VERSION "V1.7.4"

NS_ :

BS_:

BU_: DC RL RR FL FR

BO_ 1633 CAL_Static_Result_RR: 64 Vector__XXX
 SG_ CAL_start_calib_id_RR : 7|8@0+ (1,0) [0|255] "" Vector__XXX

BO_ 1121 CAL_Static_Result_RL: 64 Vector__XXX
 SG_ CAL_start_calib_id_RL : 7|8@0+ (1,0) [0|255] "" Vector__XXX

BO_ 609 CAL_Static_Result_FR: 64 Vector__XXX
 SG_ CAL_start_calib_id_FR : 7|8@0+ (1,0) [0|255] "" Vector__XXX

BO_ 97 CAL_Static_Result_FL: 64 Vector__XXX
 SG_ CAL_start_calib_id_FL : 7|8@0+ (1,0) [0|255] "" Vector__XXX

BO_ 1632 CAL_Cfg_RR: 64 Vector__XXX
 SG_ CAL_calib_id_RR : 7|8@0+ (1,0) [0|255] "" Vector__XXX
 SG_ CAL_vehicle_height_RR : 15|32@0- (1,0) [-3.4E+038|3.4E+038] ""  RR
 SG_ CAL_reserve5_RR : 455|64@0+ (1,0) [0|1.84467440737096E+019] ""  RR
 SG_ CAL_reserve4_RR : 391|64@0+ (1,0) [0|1.84467440737096E+019] ""  RR
 SG_ CAL_reserve3_RR : 327|64@0+ (1,0) [0|1.84467440737096E+019] ""  RR
 SG_ CAL_reserve2_RR : 263|64@0+ (1,0) [0|1.84467440737096E+019] ""  RR
 SG_ CAL_reserve1_RR : 239|24@0+ (1,0) [0|16777215] ""  RR
 SG_ CAL_radar_z_offset_RR : 111|32@0- (1,0) [-3.4E+038|3.4E+038] ""  RR
 SG_ CAL_radar_yaw_angle_RR : 143|32@0- (1,0) [-3.4E+038|3.4E+038] ""  RR
 SG_ CAL_radar_y_offset_RR : 79|32@0- (1,0) [-3.4E+038|3.4E+038] ""  RR
 SG_ CAL_radar_x_offset_RR : 47|32@0- (1,0) [-3.4E+038|3.4E+038] ""  RR
 SG_ CAL_radar_roll_angle_RR : 207|32@0- (1,0) [-3.4E+038|3.4E+038] ""  RR
 SG_ CAL_radar_pitch_angle_RR : 175|32@0- (1,0) [-3.4E+038|3.4E+038] ""  RR

BO_ 1120 CAL_Cfg_RL: 64 Vector__XXX
 SG_ CAL_calib_id_RL : 7|8@0+ (1,0) [0|255] "" Vector__XXX
 SG_ CAL_vehicle_height_RL : 15|32@0- (1,0) [-3.4E+038|3.4E+038] ""  RL
 SG_ CAL_reserve5_RL : 455|64@0+ (1,0) [0|1.84467440737096E+019] ""  RL
 SG_ CAL_reserve4_RL : 391|64@0+ (1,0) [0|1.84467440737096E+019] ""  RL
 SG_ CAL_reserve3_RL : 327|64@0+ (1,0) [0|1.84467440737096E+019] ""  RL
 SG_ CAL_reserve2_RL : 263|64@0+ (1,0) [0|1.84467440737096E+019] ""  RL
 SG_ CAL_reserve1_RL : 239|24@0+ (1,0) [0|16777215] ""  RL
 SG_ CAL_radar_z_offset_RL : 111|32@0- (1,0) [-3.4E+038|3.4E+038] ""  RL
 SG_ CAL_radar_yaw_angle_RL : 143|32@0- (1,0) [-3.4E+038|3.4E+038] ""  RL
 SG_ CAL_radar_y_offset_RL : 79|32@0- (1,0) [-3.4E+038|3.4E+038] ""  RL
 SG_ CAL_radar_x_offset_RL : 47|32@0- (1,0) [-3.4E+038|3.4E+038] ""  RL
 SG_ CAL_radar_roll_angle_RL : 207|32@0- (1,0) [-3.4E+038|3.4E+038] ""  RL
 SG_ CAL_radar_pitch_angle_RL : 175|32@0- (1,0) [-3.4E+038|3.4E+038] ""  RL

BO_ 608 CAL_Cfg_FR: 64 Vector__XXX
 SG_ CAL_calib_id_FR : 7|8@0+ (1,0) [0|255] "" Vector__XXX
 SG_ CAL_vehicle_height_FR : 15|32@0- (1,0) [-3.4E+038|3.4E+038] ""  FR
 SG_ CAL_reserve5_FR : 455|64@0+ (1,0) [0|1.84467440737096E+019] ""  FR
 SG_ CAL_reserve4_FR : 391|64@0+ (1,0) [0|1.84467440737096E+019] ""  FR
 SG_ CAL_reserve3_FR : 327|64@0+ (1,0) [0|1.84467440737096E+019] ""  FR
 SG_ CAL_reserve2_FR : 263|64@0+ (1,0) [0|1.84467440737096E+019] ""  FR
 SG_ CAL_reserve1_FR : 239|24@0+ (1,0) [0|16777215] ""  FR
 SG_ CAL_radar_z_offset_FR : 111|32@0- (1,0) [-3.4E+038|3.4E+038] ""  FR
 SG_ CAL_radar_yaw_angle_FR : 143|32@0- (1,0) [-3.4E+038|3.4E+038] ""  FR
 SG_ CAL_radar_y_offset_FR : 79|32@0- (1,0) [-3.4E+038|3.4E+038] ""  FR
 SG_ CAL_radar_x_offset_FR : 47|32@0- (1,0) [-3.4E+038|3.4E+038] ""  FR
 SG_ CAL_radar_roll_angle_FR : 207|32@0- (1,0) [-3.4E+038|3.4E+038] ""  FR
 SG_ CAL_radar_pitch_angle_FR : 175|32@0- (1,0) [-3.4E+038|3.4E+038] ""  FR

BO_ 96 CAL_Cfg_FL: 64 Vector__XXX
 SG_ CAL_calib_id_FL : 7|8@0+ (1,0) [0|255] "" Vector__XXX
 SG_ CAL_vehicle_height_FL : 15|32@0- (1,0) [-3.4E+038|3.4E+038] ""  FL
 SG_ CAL_reserve5_FL : 455|64@0+ (1,0) [0|1.84467440737096E+019] ""  FL
 SG_ CAL_reserve4_FL : 391|64@0+ (1,0) [0|1.84467440737096E+019] ""  FL
 SG_ CAL_reserve3_FL : 327|64@0+ (1,0) [0|1.84467440737096E+019] ""  FL
 SG_ CAL_reserve2_FL : 263|64@0+ (1,0) [0|1.84467440737096E+019] ""  FL
 SG_ CAL_reserve1_FL : 239|24@0+ (1,0) [0|16777215] ""  FL
 SG_ CAL_radar_z_offset_FL : 111|32@0- (1,0) [-3.4E+038|3.4E+038] ""  FL
 SG_ CAL_radar_yaw_angle_FL : 143|32@0- (1,0) [-3.4E+038|3.4E+038] ""  FL
 SG_ CAL_radar_y_offset_FL : 79|32@0- (1,0) [-3.4E+038|3.4E+038] ""  FL
 SG_ CAL_radar_x_offset_FL : 47|32@0- (1,0) [-3.4E+038|3.4E+038] ""  FL
 SG_ CAL_radar_roll_angle_FL : 207|32@0- (1,0) [-3.4E+038|3.4E+038] ""  FL
 SG_ CAL_radar_pitch_angle_FL : 175|32@0- (1,0) [-3.4E+038|3.4E+038] ""  FL

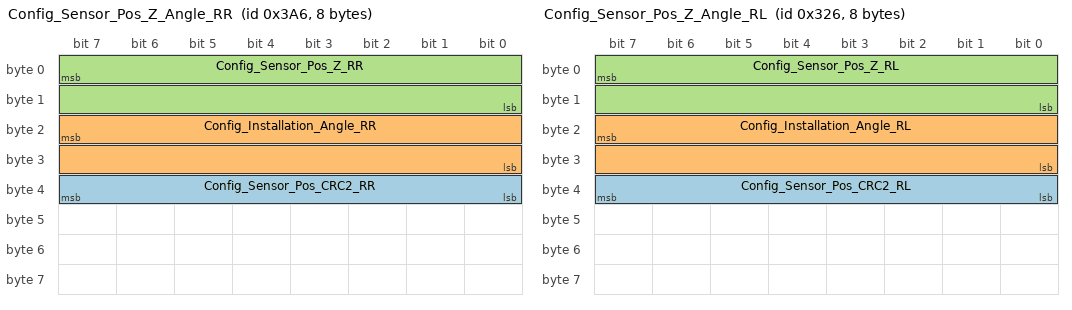
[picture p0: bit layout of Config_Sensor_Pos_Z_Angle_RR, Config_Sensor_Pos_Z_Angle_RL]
BO_ 934 Config_Sensor_Pos_Z_Angle_RR: 8 DC
 SG_ Config_Sensor_Pos_CRC2_RR : 39|8@0+ (1,0) [0|255] "N/A"  RR
 SG_ Config_Installation_Angle_RR : 23|16@0+ (1,-1800) [-1800|1800] "mm"  RR
 SG_ Config_Sensor_Pos_Z_RR : 7|16@0+ (1,0) [250|2000] "mm"  RR

BO_ 806 Config_Sensor_Pos_Z_Angle_RL: 8 DC
 SG_ Config_Sensor_Pos_CRC2_RL : 39|8@0+ (1,0) [0|255] "N/A"  RL
 SG_ Config_Installation_Angle_RL : 23|16@0+ (1,-1800) [-1800|1800] "mm"  RL
 SG_ Config_Sensor_Pos_Z_RL : 7|16@0+ (1,0) [250|2000] "mm"  RL

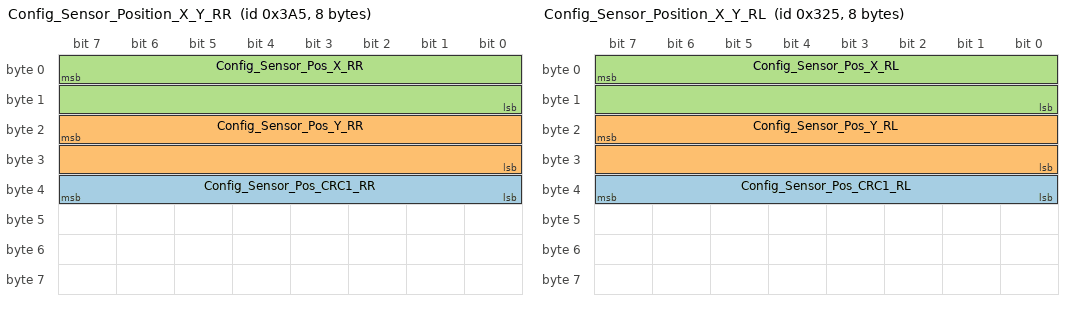
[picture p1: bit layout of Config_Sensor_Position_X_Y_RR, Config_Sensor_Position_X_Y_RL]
BO_ 933 Config_Sensor_Position_X_Y_RR: 8 DC
 SG_ Config_Sensor_Pos_CRC1_RR : 39|8@0+ (1,0) [0|255] "N/A"  RR
 SG_ Config_Sensor_Pos_Y_RR : 23|16@0+ (1,-20000) [-20000|20000] "mm"  RR
 SG_ Config_Sensor_Pos_X_RR : 7|16@0+ (1,-20000) [-20000|20000] "mm"  RR

BO_ 805 Config_Sensor_Position_X_Y_RL: 8 DC
 SG_ Config_Sensor_Pos_CRC1_RL : 39|8@0+ (1,0) [0|255] "N/A"  RL
 SG_ Config_Sensor_Pos_Y_RL : 23|16@0+ (1,-20000) [-20000|20000] "mm"  RL
 SG_ Config_Sensor_Pos_X_RL : 7|16@0+ (1,-20000) [-20000|20000] "mm"  RL

BO_ 32 Config_Mode_RR: 8 DC
 SG_ Config_Mode_CRC_RR : 15|8@0+ (1,0) [0|255] "N/A"  RR
 SG_ Config_Mode_Flag_RR : 7|8@0+ (1,0) [0|1] "N/A"  RR

BO_ 28 Config_Mode_RL: 8 DC
 SG_ Config_Mode_CRC_RL : 15|8@0+ (1,0) [0|255] "N/A"  RL
 SG_ Config_Mode_Flag_RL : 7|8@0+ (1,0) [0|1] "N/A"  RL

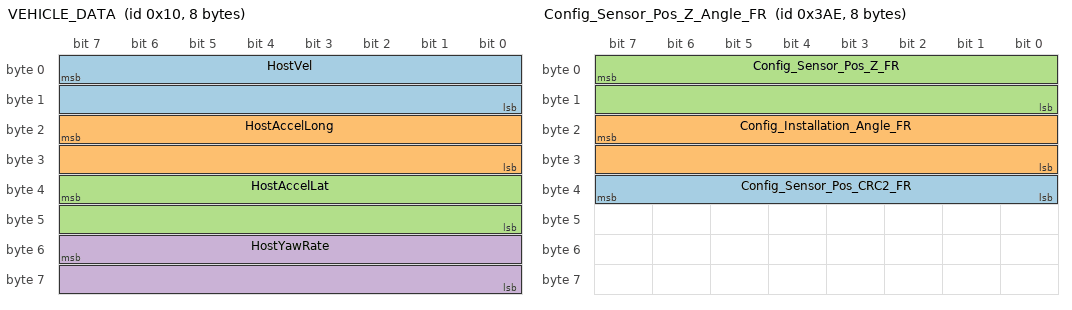
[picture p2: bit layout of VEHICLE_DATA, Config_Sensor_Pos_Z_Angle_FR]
BO_ 16 VEHICLE_DATA: 8 DC
 SG_ HostVel : 7|16@0+ (1,-2000) [-2000|14000] "cm/s"  FR,FL,RR,RL
 SG_ HostAccelLong : 23|16@0+ (1,-2000) [-2000|2000] "cm/s.s"  FR,FL,RR,RL
 SG_ HostAccelLat : 39|16@0+ (1,-2000) [-2000|2000] "cm/s.s"  FR,FL,RR,RL
 SG_ HostYawRate : 55|16@0+ (1,-2048) [-2048|2047] "1/1024 rad/sec"  FR,FL,RR,RL

BO_ 942 Config_Sensor_Pos_Z_Angle_FR: 8 DC
 SG_ Config_Sensor_Pos_CRC2_FR : 39|8@0+ (1,0) [0|255] "N/A"  FR
 SG_ Config_Installation_Angle_FR : 23|16@0+ (1,-1800) [-1800|1800] "mm"  FR
 SG_ Config_Sensor_Pos_Z_FR : 7|16@0+ (1,0) [250|2000] "mm"  FR

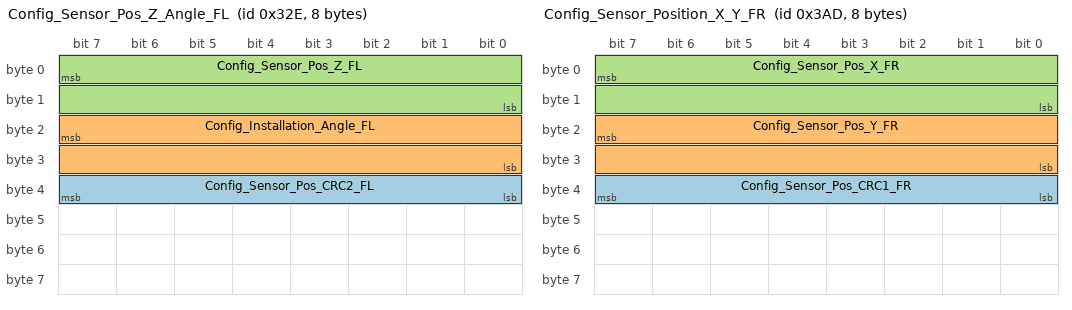
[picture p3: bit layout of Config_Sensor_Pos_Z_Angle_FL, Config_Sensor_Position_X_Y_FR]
BO_ 814 Config_Sensor_Pos_Z_Angle_FL: 8 DC
 SG_ Config_Sensor_Pos_CRC2_FL : 39|8@0+ (1,0) [0|255] "N/A"  FL
 SG_ Config_Installation_Angle_FL : 23|16@0+ (1,-1800) [-1800|1800] "mm"  FL
 SG_ Config_Sensor_Pos_Z_FL : 7|16@0+ (1,0) [250|2000] "mm"  FL

BO_ 941 Config_Sensor_Position_X_Y_FR: 8 DC
 SG_ Config_Sensor_Pos_CRC1_FR : 39|8@0+ (1,0) [0|255] "N/A"  FR
 SG_ Config_Sensor_Pos_Y_FR : 23|16@0+ (1,-20000) [-20000|20000] "mm"  FR
 SG_ Config_Sensor_Pos_X_FR : 7|16@0+ (1,-20000) [-20000|20000] "mm"  FR

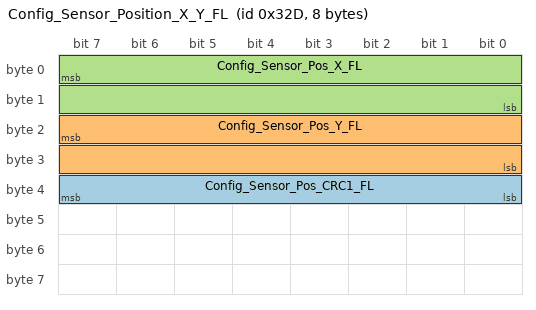
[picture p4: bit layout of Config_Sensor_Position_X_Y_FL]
BO_ 813 Config_Sensor_Position_X_Y_FL: 8 DC
 SG_ Config_Sensor_Pos_CRC1_FL : 39|8@0+ (1,0) [0|255] "N/A"  FL
 SG_ Config_Sensor_Pos_Y_FL : 23|16@0+ (1,-20000) [-20000|20000] "mm"  FL
 SG_ Config_Sensor_Pos_X_FL : 7|16@0+ (1,-20000) [-20000|20000] "mm"  FL

BO_ 24 Config_Mode_FR: 8 DC
 SG_ Config_Mode_CRC_FR : 15|8@0+ (1,0) [0|255] "N/A"  FR
 SG_ Config_Mode_Flag_FR : 7|8@0+ (1,0) [0|1] "N/A"  FR

BO_ 20 Config_Mode_FL: 8 DC
 SG_ Config_Mode_CRC_FL : 15|8@0+ (1,0) [0|255] "N/A"  FL
 SG_ Config_Mode_Flag_FL : 7|8@0+ (1,0) [0|1] "N/A"  FL

BO_ 85 Check_History_Error: 2 DC
 SG_ Check_CRC : 15|8@0+ (1,0) [0|255] ""  RR,RL,FR,FL
 SG_ Check_Request_Error : 7|8@0+ (1,0) [0|255] ""  RR,RL,FR,FL

BO_ 50 Diag_Hist_Error_Clear_FR: 20 DC
 SG_ Error_Clear_CRC_FR : 135|8@0+ (1,0) [0|255] ""  FR
 SG_ O_POPC_Index_Clear_FR : 119|8@0+ (1,0) [0|255] ""  FR
 SG_ O_POPC_Clear_FR : 107|4@0+ (1,0) [0|15] ""  FR
 SG_ O_PRPC_SIDI_Clear_FR : 111|4@0+ (1,0) [0|15] ""  FR
 SG_ O_PRPC_INV_Clear_FR : 99|4@0+ (1,0) [0|15] ""  FR
 SG_ O_Reset_Clear_FR : 103|4@0+ (1,0) [0|15] ""  FR
 SG_ P_INV_Intrinsics_Clear_FR : 75|4@0+ (1,0) [0|15] ""  FR
 SG_ P_INV_Memory_Clear_FR : 67|4@0+ (1,0) [0|15] ""  FR
 SG_ C_CAN_BusOff_Clear_FR : 31|4@0+ (1,0) [0|15] ""  FR
 SG_ C_CAN_Error_Clear_FR : 19|4@0+ (1,0) [0|15] ""  FR
 SG_ H_PMIC_Volt_Clear_FR : 15|4@0+ (1,0) [0|15] ""  FR
 SG_ H_Under_Volt_Clear_FR : 3|4@0+ (1,0) [0|15] ""  FR
 SG_ H_Over_Volt_Clear_FR : 7|4@0+ (1,0) [0|15] ""  FR

BO_ 49 Diag_Hist_Error_Clear_FL: 20 DC
 SG_ Error_Clear_CRC_FL : 135|8@0+ (1,0) [0|255] ""  FL
 SG_ O_POPC_Index_Clear_FL : 119|8@0+ (1,0) [0|255] ""  FL
 SG_ O_POPC_Clear_FL : 107|4@0+ (1,0) [0|15] ""  FL
 SG_ O_PRPC_SIDI_Clear_FL : 111|4@0+ (1,0) [0|15] ""  FL
 SG_ O_PRPC_INV_Clear_FL : 99|4@0+ (1,0) [0|15] ""  FL
 SG_ O_Reset_Clear_FL : 103|4@0+ (1,0) [0|15] ""  FL
 SG_ P_INV_Intrinsics_Clear_FL : 75|4@0+ (1,0) [0|15] ""  FL
 SG_ P_INV_Memory_Clear_FL : 67|4@0+ (1,0) [0|15] ""  FL
 SG_ C_CAN_BusOff_Clear_FL : 31|4@0+ (1,0) [0|15] ""  FL
 SG_ C_CAN_Error_Clear_FL : 19|4@0+ (1,0) [0|15] ""  FL
 SG_ H_PMIC_Volt_Clear_FL : 15|4@0+ (1,0) [0|15] ""  FL
 SG_ H_Under_Volt_Clear_FL : 3|4@0+ (1,0) [0|15] ""  FL
 SG_ H_Over_Volt_Clear_FL : 7|4@0+ (1,0) [0|15] ""  FL

BO_ 52 Diag_Hist_Error_Clear_RR: 20 DC
 SG_ Error_Clear_CRC_RR : 135|8@0+ (1,0) [0|255] ""  RR
 SG_ O_POPC_Index_Clear_RR : 119|8@0+ (1,0) [0|255] ""  RR
 SG_ O_POPC_Clear_RR : 107|4@0+ (1,0) [0|15] ""  RR
 SG_ O_PRPC_SIDI_Clear_RR : 111|4@0+ (1,0) [0|15] ""  RR
 SG_ O_PRPC_INV_Clear_RR : 99|4@0+ (1,0) [0|15] ""  RR
 SG_ O_Reset_Clear_RR : 103|4@0+ (1,0) [0|15] ""  RR
 SG_ P_INV_Intrinsics_Clear_RR : 75|4@0+ (1,0) [0|15] ""  RR
 SG_ P_INV_Memory_Clear_RR : 67|4@0+ (1,0) [0|15] ""  RR
 SG_ C_CAN_BusOff_Clear_RR : 31|4@0+ (1,0) [0|15] ""  RR
 SG_ C_CAN_Error_Clear_RR : 19|4@0+ (1,0) [0|15] ""  RR
 SG_ H_PMIC_Volt_Clear_RR : 15|4@0+ (1,0) [0|15] ""  RR
 SG_ H_Under_Volt_Clear_RR : 3|4@0+ (1,0) [0|15] ""  RR
 SG_ H_Over_Volt_Clear_RR : 7|4@0+ (1,0) [0|15] ""  RR

BO_ 51 Diag_Hist_Error_Clear_RL: 20 DC
 SG_ Error_Clear_CRC_RL : 135|8@0+ (1,0) [0|255] ""  RL
 SG_ O_POPC_Index_Clear_RL : 119|8@0+ (1,0) [0|255] ""  RL
 SG_ O_POPC_Clear_RL : 107|4@0+ (1,0) [0|15] ""  RL
 SG_ O_PRPC_SIDI_Clear_RL : 111|4@0+ (1,0) [0|15] ""  RL
 SG_ O_PRPC_INV_Clear_RL : 99|4@0+ (1,0) [0|15] ""  RL
 SG_ O_Reset_Clear_RL : 103|4@0+ (1,0) [0|15] ""  RL
 SG_ P_INV_Intrinsics_Clear_RL : 75|4@0+ (1,0) [0|15] ""  RL
 SG_ P_INV_Memory_Clear_RL : 67|4@0+ (1,0) [0|15] ""  RL
 SG_ C_CAN_BusOff_Clear_RL : 31|4@0+ (1,0) [0|15] ""  RL
 SG_ C_CAN_Error_Clear_RL : 19|4@0+ (1,0) [0|15] ""  RL
 SG_ H_PMIC_Volt_Clear_RL : 15|4@0+ (1,0) [0|15] ""  RL
 SG_ H_Under_Volt_Clear_RL : 3|4@0+ (1,0) [0|15] ""  RL
 SG_ H_Over_Volt_Clear_RL : 7|4@0+ (1,0) [0|15] ""  RL

CM_ BO_ 934 "Configure the Z Position and Installation Angle of the Radar";
CM_ SG_ 934 Config_Sensor_Pos_CRC2_RR "CRC";
CM_ SG_ 934 Config_Installation_Angle_RR "Ten Times the Actual Value of  Installation Angle in deg";
CM_ SG_ 934 Config_Sensor_Pos_Z_RR "The Actual Value of  Z Position in mm";
CM_ BO_ 806 "Configure the Z Position and Installation Angle of the Radar";
CM_ SG_ 806 Config_Sensor_Pos_CRC2_RL "CRC";
CM_ SG_ 806 Config_Installation_Angle_RL "Ten Times the Actual Value of  Installation Angle in deg";
CM_ SG_ 806 Config_Sensor_Pos_Z_RL "The Actual Value of  Z Position in mm";
CM_ BO_ 933 "Configure the X Position and Y Position of the Radar";
CM_ SG_ 933 Config_Sensor_Pos_CRC1_RR "CRC";
CM_ SG_ 933 Config_Sensor_Pos_Y_RR "The Actual Value of  Y Position in mm";
CM_ SG_ 933 Config_Sensor_Pos_X_RR "The Actual Value of  X Position in mm";
CM_ BO_ 805 "Configure the X Position and Y Position of the Radar";
CM_ SG_ 805 Config_Sensor_Pos_CRC1_RL "CRC";
CM_ SG_ 805 Config_Sensor_Pos_Y_RL "The Actual Value of  Y Position in mm";
CM_ SG_ 805 Config_Sensor_Pos_X_RL "The Actual Value of  X Position in mm";
CM_ BO_ 32 "Configure the Radar to Config Mode or Normal Mode";
CM_ SG_ 32 Config_Mode_CRC_RR "CRC";
CM_ SG_ 32 Config_Mode_Flag_RR "0: Normal Mode
1: Config Mode";
CM_ BO_ 28 "Configure the Radar to Config Mode or Normal Mode";
CM_ SG_ 28 Config_Mode_CRC_RL "CRC";
CM_ SG_ 28 Config_Mode_Flag_RL "0: Normal Mode
1: Config Mode";
CM_ BO_ 16 "Contains the Vehicle Data";
CM_ SG_ 16 HostVel "Host velocity";
CM_ SG_ 16 HostAccelLong "Longitudinal host acceleration in cm/s^2";
CM_ SG_ 16 HostAccelLat "Lateral host acceleration in cm/s^2";
CM_ SG_ 16 HostYawRate "Host yaw rate in 1/1024 rad/s";
CM_ BO_ 942 "Configure the Z Position and Installation Angle of the Radar";
CM_ SG_ 942 Config_Sensor_Pos_CRC2_FR "CRC";
CM_ SG_ 942 Config_Installation_Angle_FR "Ten Times the Actual Value of  Installation Angle in deg";
CM_ SG_ 942 Config_Sensor_Pos_Z_FR "The Actual Value of  Z Position in mm";
CM_ BO_ 814 "Configure the Z Position and Installation Angle of the Radar";
CM_ SG_ 814 Config_Sensor_Pos_CRC2_FL "CRC";
CM_ SG_ 814 Config_Installation_Angle_FL "Ten Times the Actual Value of  Installation Angle in deg";
CM_ SG_ 814 Config_Sensor_Pos_Z_FL "The Actual Value of  Z Position in mm";
CM_ BO_ 941 "Configure the X Position and Y Position of the Radar";
CM_ SG_ 941 Config_Sensor_Pos_CRC1_FR "CRC";
CM_ SG_ 941 Config_Sensor_Pos_Y_FR "The Actual Value of  Y Position in mm";
CM_ SG_ 941 Config_Sensor_Pos_X_FR "The Actual Value of  X Position in mm";
CM_ BO_ 813 "Configure the X Position and Y Position of the Radar";
CM_ SG_ 813 Config_Sensor_Pos_CRC1_FL "CRC";
CM_ SG_ 813 Config_Sensor_Pos_Y_FL "The Actual Value of  Y Position in mm";
CM_ SG_ 813 Config_Sensor_Pos_X_FL "The Actual Value of  X Position in mm";
CM_ BO_ 24 "Configure the Radar to Config Mode or Normal Mode";
CM_ SG_ 24 Config_Mode_CRC_FR "CRC";
CM_ SG_ 24 Config_Mode_Flag_FR "0: Normal Mode
1: Config Mode";
CM_ BO_ 20 "Configure the Radar to Config Mode or Normal Mode";
CM_ SG_ 20 Config_Mode_CRC_FL "CRC";
CM_ SG_ 20 Config_Mode_Flag_FL "0: Normal Mode
1: Config Mode";
CM_ BO_ 85 "Request history fault output";
CM_ SG_ 85 Check_CRC "Check_CRC";
CM_ SG_ 85 Check_Request_Error "Request history fault output";
CM_ BO_ 50 "Clear history faults";
CM_ SG_ 50 Error_Clear_CRC_FR "Error_Clear_CRC";
CM_ SG_ 50 O_POPC_Index_Clear_FR "Record POPC assertion location, clear history error";
CM_ SG_ 50 O_POPC_Clear_FR "POSTPROCESS_ERROR, clear history error";
CM_ SG_ 50 O_PRPC_SIDI_Clear_FR "PREPROCESS_ERROR, other prpc error, clear history error";
CM_ SG_ 50 O_PRPC_INV_Clear_FR "PREPROCESS_ERROR, No point output, clear history error";
CM_ SG_ 50 O_Reset_Clear_FR "RESET_ERROR, clear history error";
CM_ SG_ 50 P_INV_Intrinsics_Clear_FR "EOL, Internal reference abnormality, clear history error";
CM_ SG_ 50 P_INV_Memory_Clear_FR "Memory/FLASH, Parameter storage exception, clear history error";
CM_ SG_ 50 C_CAN_BusOff_Clear_FR "Communication, BusOff, clear history error";
CM_ SG_ 50 C_CAN_Error_Clear_FR "Communication, Error Counter, clear history error";
CM_ SG_ 50 H_PMIC_Volt_Clear_FR "Abnormal SOC voltage, clear history error";
CM_ SG_ 50 H_Under_Volt_Clear_FR "Voltag_undermin, clear history error";
CM_ SG_ 50 H_Over_Volt_Clear_FR "Voltage_overmax, clear history error";
CM_ BO_ 49 "Clear history faults";
CM_ SG_ 49 Error_Clear_CRC_FL "Error_Clear_CRC";
CM_ SG_ 49 O_POPC_Index_Clear_FL "Record POPC assertion location, clear history error";
CM_ SG_ 49 O_POPC_Clear_FL "POSTPROCESS_ERROR, clear history error";
CM_ SG_ 49 O_PRPC_SIDI_Clear_FL "PREPROCESS_ERROR, other prpc error, clear history error";
CM_ SG_ 49 O_PRPC_INV_Clear_FL "PREPROCESS_ERROR, No point output, clear history error";
CM_ SG_ 49 O_Reset_Clear_FL "RESET_ERROR, clear history error";
CM_ SG_ 49 P_INV_Intrinsics_Clear_FL "EOL, Internal reference abnormality, clear history error";
CM_ SG_ 49 P_INV_Memory_Clear_FL "Memory/FLASH, Parameter storage exception, clear history error";
CM_ SG_ 49 C_CAN_BusOff_Clear_FL "Communication, BusOff, clear history error";
CM_ SG_ 49 C_CAN_Error_Clear_FL "Communication, Error Counter, clear history error";
CM_ SG_ 49 H_PMIC_Volt_Clear_FL "Abnormal SOC voltage, clear history error";
CM_ SG_ 49 H_Under_Volt_Clear_FL "Voltag_undermin, clear history error";
CM_ SG_ 49 H_Over_Volt_Clear_FL "Voltage_overmax, clear history error";
CM_ BO_ 52 "Clear history faults";
CM_ SG_ 52 Error_Clear_CRC_RR "Error_Clear_CRC";
CM_ SG_ 52 O_POPC_Index_Clear_RR "Record POPC assertion location, clear history error";
CM_ SG_ 52 O_POPC_Clear_RR "POSTPROCESS_ERROR, clear history error";
CM_ SG_ 52 O_PRPC_SIDI_Clear_RR "PREPROCESS_ERROR, other prpc error, clear history error";
CM_ SG_ 52 O_PRPC_INV_Clear_RR "PREPROCESS_ERROR, No point output, clear history error";
CM_ SG_ 52 O_Reset_Clear_RR "RESET_ERROR, clear history error";
CM_ SG_ 52 P_INV_Intrinsics_Clear_RR "EOL, Internal reference abnormality, clear history error";
CM_ SG_ 52 P_INV_Memory_Clear_RR "Memory/FLASH, Parameter storage exception, clear history error";
CM_ SG_ 52 C_CAN_BusOff_Clear_RR "Communication, BusOff, clear history error";
CM_ SG_ 52 C_CAN_Error_Clear_RR "Communication, Error Counter, clear history error";
CM_ SG_ 52 H_PMIC_Volt_Clear_RR "Abnormal SOC voltage, clear history error";
CM_ SG_ 52 H_Under_Volt_Clear_RR "Voltag_undermin, clear history error";
CM_ SG_ 52 H_Over_Volt_Clear_RR "Voltage_overmax, clear history error";
CM_ BO_ 51 "Clear history faults";
CM_ SG_ 51 Error_Clear_CRC_RL "Error_Clear_CRC";
CM_ SG_ 51 O_POPC_Index_Clear_RL "Record POPC assertion location, clear history error";
CM_ SG_ 51 O_POPC_Clear_RL "POSTPROCESS_ERROR, clear history error";
CM_ SG_ 51 O_PRPC_SIDI_Clear_RL "PREPROCESS_ERROR, other prpc error, clear history error";
CM_ SG_ 51 O_PRPC_INV_Clear_RL "PREPROCESS_ERROR, No point output, clear history error";
CM_ SG_ 51 O_Reset_Clear_RL "RESET_ERROR, clear history error";
CM_ SG_ 51 P_INV_Intrinsics_Clear_RL "EOL, Internal reference abnormality, clear history error";
CM_ SG_ 51 P_INV_Memory_Clear_RL "Memory/FLASH, Parameter storage exception, clear history error";
CM_ SG_ 51 C_CAN_BusOff_Clear_RL "Communication, BusOff, clear history error";
CM_ SG_ 51 C_CAN_Error_Clear_RL "Communication, Error Counter, clear history error";
CM_ SG_ 51 H_PMIC_Volt_Clear_RL "Abnormal SOC voltage, clear history error";
CM_ SG_ 51 H_Under_Volt_Clear_RL "Voltag_undermin, clear history error";
CM_ SG_ 51 H_Over_Volt_Clear_RL "Voltage_overmax, clear history error";
BA_DEF_ SG_  "GenSigStartValue" FLOAT -1.79769313486232E+019 1.84467440737096E+019;
BA_DEF_ BO_  "GenMsgCycleTime" FLOAT 0 300000;
BA_DEF_ BO_  "GenMsgSendType" ENUM  "cyclic","spontaneous","cyclicIfActive","spontaneousWithDelay";
BA_DEF_  "BaudRate" FLOAT 1000 1000000;
BA_DEF_ BO_  "CANFD_BRS" ENUM  "0","1";
BA_DEF_  "DBName" STRING ;
BA_DEF_  "BusType" STRING ;
BA_DEF_ BO_  "VFrameFormat" ENUM  "StandardCAN","ExtendedCAN","reserved","reserved","reserved","reserved","reserved","reserved","reserved","reserved","reserved","reserved","reserved","reserved","StandardCAN_FD","ExtendedCAN_FD";
BA_DEF_DEF_  "GenSigStartValue" 0;
BA_DEF_DEF_  "GenMsgCycleTime" 0;
BA_DEF_DEF_  "GenMsgSendType" "";
BA_DEF_DEF_  "BaudRate" 2000;
BA_DEF_DEF_  "CANFD_BRS" "1";
BA_DEF_DEF_  "DBName" "";
BA_DEF_DEF_  "BusType" "";
BA_DEF_DEF_  "VFrameFormat" "StandardCAN_FD";
BA_ "BusType" "CAN FD";
BA_ "DBName" "VCANFD";
BA_ "GenMsgCycleTime" BO_ 934 1000;
BA_ "GenMsgSendType" BO_ 934 0;
BA_ "GenMsgCycleTime" BO_ 806 1000;
BA_ "GenMsgSendType" BO_ 806 0;
BA_ "GenMsgCycleTime" BO_ 933 1000;
BA_ "GenMsgSendType" BO_ 933 0;
BA_ "GenMsgCycleTime" BO_ 805 1000;
BA_ "GenMsgSendType" BO_ 805 0;
BA_ "GenMsgCycleTime" BO_ 32 1000;
BA_ "GenMsgSendType" BO_ 32 0;
BA_ "GenMsgSendType" BO_ 28 0;
BA_ "GenMsgCycleTime" BO_ 28 1000;
BA_ "GenMsgSendType" BO_ 16 0;
BA_ "GenMsgCycleTime" BO_ 16 25;
BA_ "GenMsgCycleTime" BO_ 942 1000;
BA_ "GenMsgSendType" BO_ 942 0;
BA_ "GenMsgCycleTime" BO_ 814 1000;
BA_ "GenMsgSendType" BO_ 814 0;
BA_ "GenMsgCycleTime" BO_ 941 1000;
BA_ "GenMsgSendType" BO_ 941 0;
BA_ "GenMsgCycleTime" BO_ 813 1000;
BA_ "GenMsgSendType" BO_ 813 0;
BA_ "GenMsgCycleTime" BO_ 24 1000;
BA_ "GenMsgSendType" BO_ 24 0;
BA_ "GenMsgSendType" BO_ 20 0;
BA_ "GenMsgCycleTime" BO_ 20 1000;
BA_ "GenMsgSendType" BO_ 85 1;
BA_ "GenMsgSendType" BO_ 50 1;
BA_ "GenMsgSendType" BO_ 49 1;
BA_ "GenMsgSendType" BO_ 52 1;
BA_ "GenMsgSendType" BO_ 51 1;
BA_ "GenSigStartValue" SG_ 934 Config_Installation_Angle_RR 1800;
BA_ "GenSigStartValue" SG_ 934 Config_Sensor_Pos_Z_RR 500;
BA_ "GenSigStartValue" SG_ 806 Config_Installation_Angle_RL 1800;
BA_ "GenSigStartValue" SG_ 806 Config_Sensor_Pos_Z_RL 500;
BA_ "GenSigStartValue" SG_ 933 Config_Sensor_Pos_Y_RR 20000;
BA_ "GenSigStartValue" SG_ 933 Config_Sensor_Pos_X_RR 20000;
BA_ "GenSigStartValue" SG_ 805 Config_Sensor_Pos_Y_RL 20000;
BA_ "GenSigStartValue" SG_ 805 Config_Sensor_Pos_X_RL 20000;
BA_ "GenSigStartValue" SG_ 16 HostVel 2000;
BA_ "GenSigStartValue" SG_ 16 HostAccelLong 2000;
BA_ "GenSigStartValue" SG_ 16 HostAccelLat 2000;
BA_ "GenSigStartValue" SG_ 16 HostYawRate 2048;
BA_ "GenSigStartValue" SG_ 942 Config_Installation_Angle_FR 1800;
BA_ "GenSigStartValue" SG_ 942 Config_Sensor_Pos_Z_FR 500;
BA_ "GenSigStartValue" SG_ 814 Config_Installation_Angle_FL 1800;
BA_ "GenSigStartValue" SG_ 814 Config_Sensor_Pos_Z_FL 500;
BA_ "GenSigStartValue" SG_ 941 Config_Sensor_Pos_Y_FR 20000;
BA_ "GenSigStartValue" SG_ 941 Config_Sensor_Pos_X_FR 20000;
BA_ "GenSigStartValue" SG_ 813 Config_Sensor_Pos_Y_FL 20000;
BA_ "GenSigStartValue" SG_ 813 Config_Sensor_Pos_X_FL 20000;
SIG_GROUP_ 16 VEHICLE_DATA 1 : HostVel HostAccelLong HostAccelLat HostYawRate;
SIG_VALTYPE_ 1632 CAL_vehicle_height_RR : 1;
SIG_VALTYPE_ 1632 CAL_radar_z_offset_RR : 1;
SIG_VALTYPE_ 1632 CAL_radar_yaw_angle_RR : 1;
SIG_VALTYPE_ 1632 CAL_radar_y_offset_RR : 1;
SIG_VALTYPE_ 1632 CAL_radar_x_offset_RR : 1;
SIG_VALTYPE_ 1632 CAL_radar_roll_angle_RR : 1;
SIG_VALTYPE_ 1632 CAL_radar_pitch_angle_RR : 1;
SIG_VALTYPE_ 1120 CAL_vehicle_height_RL : 1;
SIG_VALTYPE_ 1120 CAL_radar_z_offset_RL : 1;
SIG_VALTYPE_ 1120 CAL_radar_yaw_angle_RL : 1;
SIG_VALTYPE_ 1120 CAL_radar_y_offset_RL : 1;
SIG_VALTYPE_ 1120 CAL_radar_x_offset_RL : 1;
SIG_VALTYPE_ 1120 CAL_radar_roll_angle_RL : 1;
SIG_VALTYPE_ 1120 CAL_radar_pitch_angle_RL : 1;
SIG_VALTYPE_ 608 CAL_vehicle_height_FR : 1;
SIG_VALTYPE_ 608 CAL_radar_z_offset_FR : 1;
SIG_VALTYPE_ 608 CAL_radar_yaw_angle_FR : 1;
SIG_VALTYPE_ 608 CAL_radar_y_offset_FR : 1;
SIG_VALTYPE_ 608 CAL_radar_x_offset_FR : 1;
SIG_VALTYPE_ 608 CAL_radar_roll_angle_FR : 1;
SIG_VALTYPE_ 608 CAL_radar_pitch_angle_FR : 1;
SIG_VALTYPE_ 96 CAL_vehicle_height_FL : 1;
SIG_VALTYPE_ 96 CAL_radar_z_offset_FL : 1;
SIG_VALTYPE_ 96 CAL_radar_yaw_angle_FL : 1;
SIG_VALTYPE_ 96 CAL_radar_y_offset_FL : 1;
SIG_VALTYPE_ 96 CAL_radar_x_offset_FL : 1;
SIG_VALTYPE_ 96 CAL_radar_roll_angle_FL : 1;
SIG_VALTYPE_ 96 CAL_radar_pitch_angle_FL : 1;
